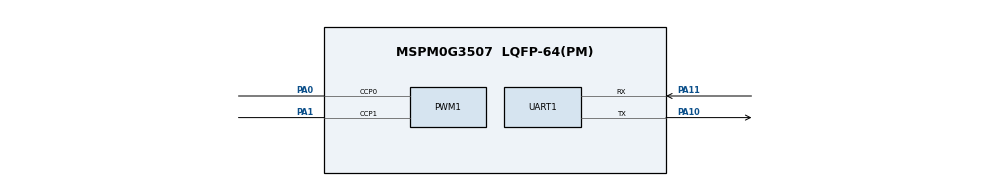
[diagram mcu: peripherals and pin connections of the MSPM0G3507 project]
/**
 * These arguments were used when this file was generated. They will be automatically applied on subsequent loads
 * via the GUI or CLI. Run CLI with '--help' for additional information on how to override these arguments.
 * @cliArgs --device "MSPM0G350X" --part "Default" --package "LQFP-64(PM)" --product "mspm0_sdk@2.10.00.04"
 * @v2CliArgs --device "MSPM0G3507" --package "LQFP-64(PM)" --product "mspm0_sdk@2.10.00.04"
 * @versions {"tool":"1.26.2+4477"}
 */

/**
 * Import the modules used in this configuration.
 */
const PWM    = scripting.addModule("/ti/driverlib/PWM", {}, false);
const PWM1   = PWM.addInstance();
const SYSCTL = scripting.addModule("/ti/driverlib/SYSCTL");
const UART   = scripting.addModule("/ti/driverlib/UART", {}, false);
const UART1  = UART.addInstance();

/**
 * Write custom configuration values to the imported modules.
 */
const divider9       = system.clockTree["UDIV"];
divider9.divideValue = 2;

const multiplier2         = system.clockTree["PLL_QDIV"];
multiplier2.multiplyValue = 4;

const mux4       = system.clockTree["EXHFMUX"];
mux4.inputSelect = "EXHFMUX_XTAL";

const mux8       = system.clockTree["HSCLKMUX"];
mux8.inputSelect = "HSCLKMUX_SYSPLL0";

const mux12       = system.clockTree["SYSPLLMUX"];
mux12.inputSelect = "zSYSPLLMUX_HFCLK";

const pinFunction4     = system.clockTree["HFXT"];
pinFunction4.enable    = true;
pinFunction4.inputFreq = 40;

PWM1.$name                              = "BLDC";
PWM1.peripheral.$assign                 = "TIMA0";
PWM1.peripheral.ccp0Pin.$assign         = "PA0";
PWM1.peripheral.ccp1Pin.$assign         = "PA1";
PWM1.PWM_CHANNEL_0.$name                = "ti_driverlib_pwm_PWMTimerCC0";
PWM1.PWM_CHANNEL_1.$name                = "ti_driverlib_pwm_PWMTimerCC1";
PWM1.ccp0PinConfig.$name                = "ti_driverlib_gpio_GPIOPinGeneric0";
PWM1.ccp0PinConfig.direction            = scripting.forceWrite("OUTPUT");
PWM1.ccp0PinConfig.hideOutputInversion  = scripting.forceWrite(false);
PWM1.ccp0PinConfig.onlyInternalResistor = scripting.forceWrite(false);
PWM1.ccp0PinConfig.passedPeripheralType = scripting.forceWrite("Digital");
PWM1.ccp1PinConfig.$name                = "ti_driverlib_gpio_GPIOPinGeneric1";
PWM1.ccp1PinConfig.direction            = scripting.forceWrite("OUTPUT");
PWM1.ccp1PinConfig.hideOutputInversion  = scripting.forceWrite(false);
PWM1.ccp1PinConfig.onlyInternalResistor = scripting.forceWrite(false);
PWM1.ccp1PinConfig.passedPeripheralType = scripting.forceWrite("Digital");

const Board = scripting.addModule("/ti/driverlib/Board", {}, false);

SYSCTL.forceDefaultClkConfig = true;

UART1.$name                            = "step";
UART1.targetBaudRate                   = 115200;
UART1.peripheral.$assign               = "UART0";
UART1.peripheral.rxPin.$assign         = "PA11";
UART1.peripheral.txPin.$assign         = "PA10";
UART1.txPinConfig.$name                = "ti_driverlib_gpio_GPIOPinGeneric2";
UART1.txPinConfig.direction            = scripting.forceWrite("OUTPUT");
UART1.txPinConfig.hideOutputInversion  = scripting.forceWrite(false);
UART1.txPinConfig.onlyInternalResistor = scripting.forceWrite(false);
UART1.txPinConfig.passedPeripheralType = scripting.forceWrite("Digital");
UART1.rxPinConfig.$name                = "ti_driverlib_gpio_GPIOPinGeneric3";
UART1.rxPinConfig.hideOutputInversion  = scripting.forceWrite(false);
UART1.rxPinConfig.onlyInternalResistor = scripting.forceWrite(false);
UART1.rxPinConfig.passedPeripheralType = scripting.forceWrite("Digital");

/**
 * Pinmux solution for unlocked pins/peripherals. This ensures that minor changes to the automatic solver in a future
 * version of the tool will not impact the pinmux you originally saw.  These lines can be completely deleted in order to
 * re-solve from scratch.
 */
pinFunction4.peripheral.$suggestSolution           = "SYSCTL";
pinFunction4.peripheral.hfxInPin.$suggestSolution  = "PA5";
pinFunction4.peripheral.hfxOutPin.$suggestSolution = "PA6";
Board.peripheral.$suggestSolution                  = "DEBUGSS";
Board.peripheral.swclkPin.$suggestSolution         = "PA20";
Board.peripheral.swdioPin.$suggestSolution         = "PA19";
SYSCTL.peripheral.$suggestSolution                 = "SYSCTL";
